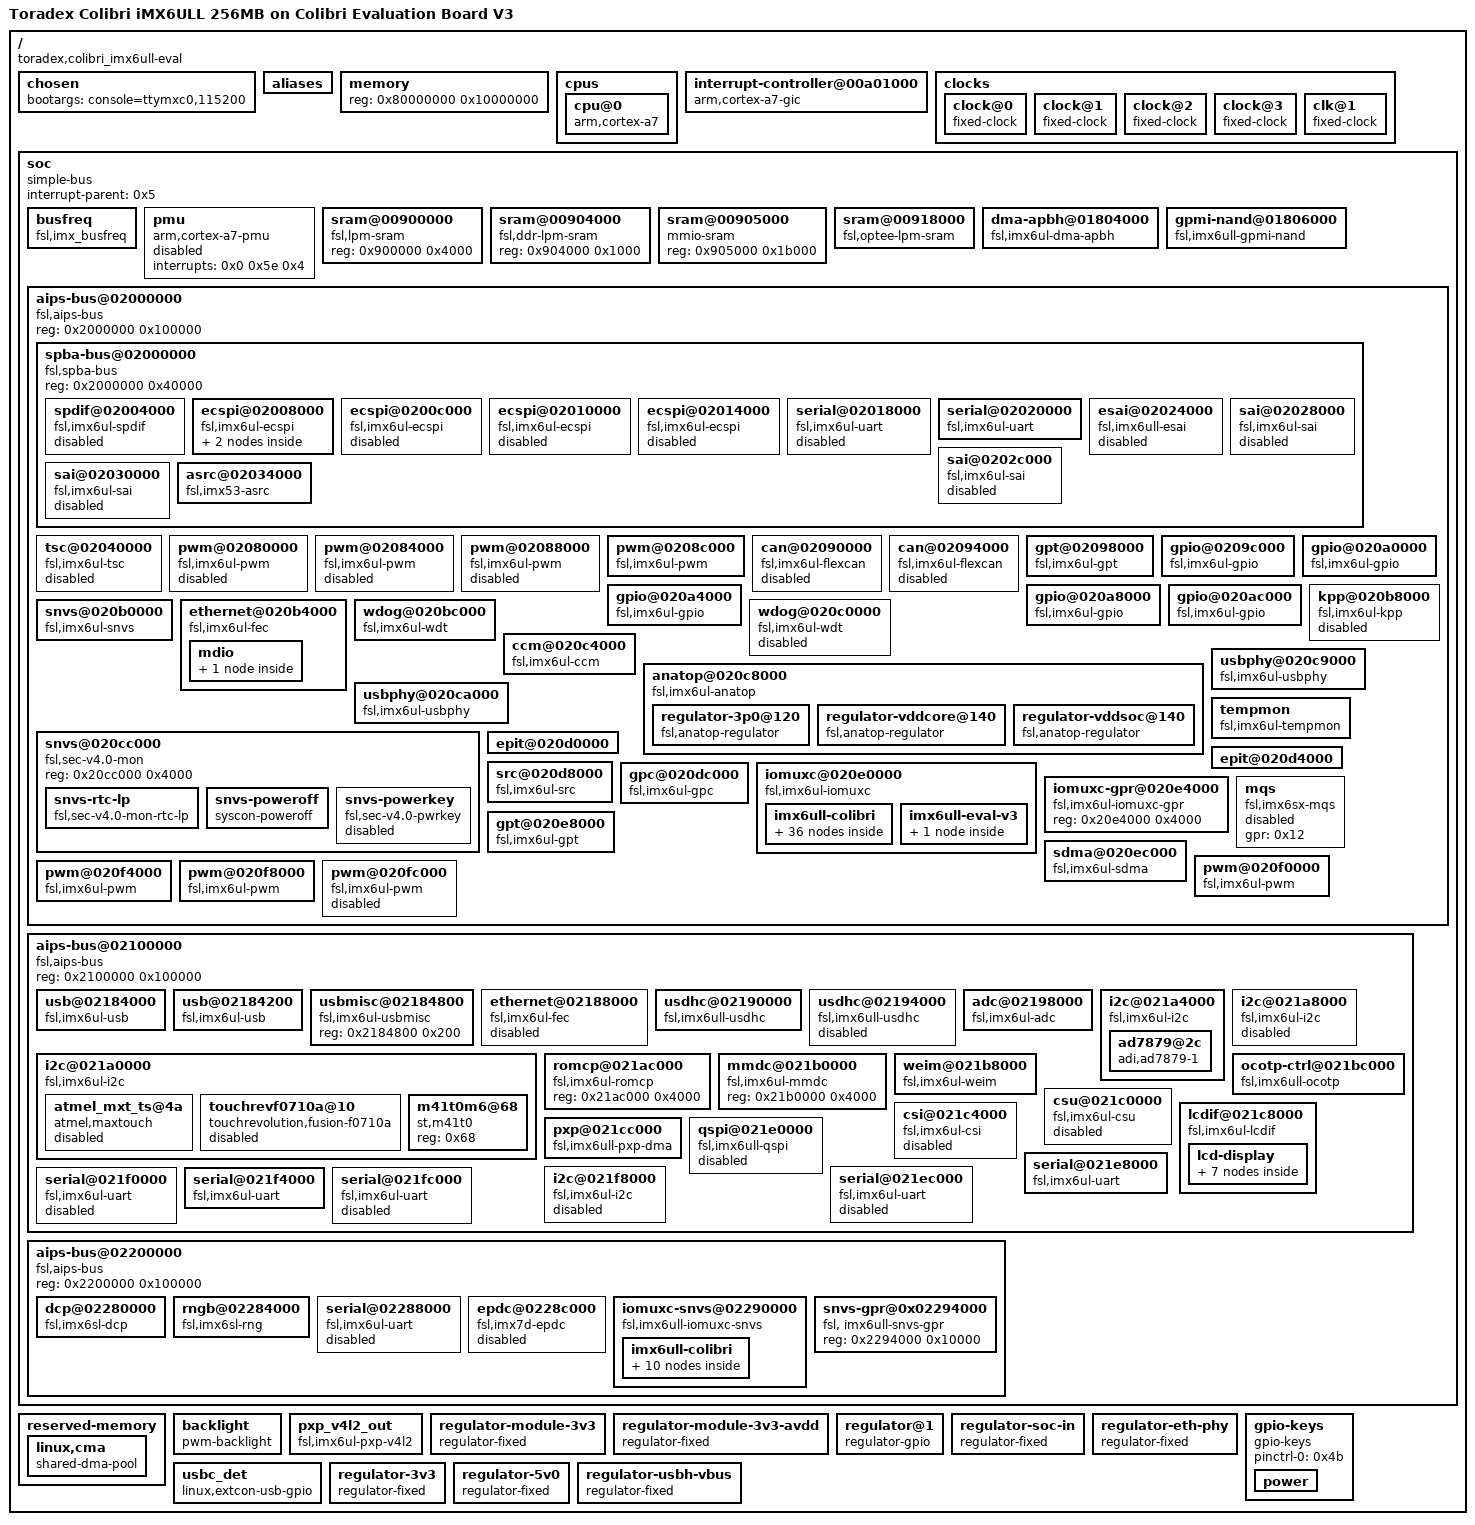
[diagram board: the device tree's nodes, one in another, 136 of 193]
/dts-v1/;

/ {
	#address-cells = <0x1>;
	#size-cells = <0x1>;
	model = "Toradex Colibri iMX6ULL 256MB on Colibri Evaluation Board V3";
	compatible = "toradex,colibri_imx6ull-eval", "fsl,imx6ull";

	chosen {
		bootargs = "console=ttymxc0,115200";
	};

	aliases {
		can0 = "/soc/aips-bus@02000000/can@02090000";
		can1 = "/soc/aips-bus@02000000/can@02094000";
		ethernet0 = "/soc/aips-bus@02000000/ethernet@020b4000";
		ethernet1 = "/soc/aips-bus@02100000/ethernet@02188000";
		gpio0 = "/soc/aips-bus@02000000/gpio@0209c000";
		gpio1 = "/soc/aips-bus@02000000/gpio@020a0000";
		gpio2 = "/soc/aips-bus@02000000/gpio@020a4000";
		gpio3 = "/soc/aips-bus@02000000/gpio@020a8000";
		gpio4 = "/soc/aips-bus@02000000/gpio@020ac000";
		i2c0 = "/soc/aips-bus@02100000/i2c@021a0000";
		i2c1 = "/soc/aips-bus@02100000/i2c@021a4000";
		i2c2 = "/soc/aips-bus@02100000/i2c@021a8000";
		i2c3 = "/soc/aips-bus@02100000/i2c@021f8000";
		mmc0 = "/soc/aips-bus@02100000/usdhc@02190000";
		mmc1 = "/soc/aips-bus@02100000/usdhc@02194000";
		serial0 = "/soc/aips-bus@02000000/spba-bus@02000000/serial@02020000";
		serial1 = "/soc/aips-bus@02100000/serial@021e8000";
		serial2 = "/soc/aips-bus@02100000/serial@021ec000";
		serial3 = "/soc/aips-bus@02100000/serial@021f0000";
		serial4 = "/soc/aips-bus@02100000/serial@021f4000";
		serial5 = "/soc/aips-bus@02100000/serial@021fc000";
		serial6 = "/soc/aips-bus@02000000/spba-bus@02000000/serial@02018000";
		serial7 = "/soc/aips-bus@02200000/serial@02288000";
		spi0 = "/soc/aips-bus@02000000/spba-bus@02000000/ecspi@02008000";
		spi1 = "/soc/aips-bus@02000000/spba-bus@02000000/ecspi@0200c000";
		spi2 = "/soc/aips-bus@02000000/spba-bus@02000000/ecspi@02010000";
		spi3 = "/soc/aips-bus@02000000/spba-bus@02000000/ecspi@02014000";
		usbphy0 = "/soc/aips-bus@02000000/usbphy@020c9000";
		usbphy1 = "/soc/aips-bus@02000000/usbphy@020ca000";
	};

	memory {
		device_type = "memory";
		reg = <0x80000000 0x10000000>;
	};

	cpus {
		#address-cells = <0x1>;
		#size-cells = <0x0>;

		cpu@0 {
			compatible = "arm,cortex-a7";
			device_type = "cpu";
			reg = <0x0>;
			clock-latency = <0xee6c>;
			operating-points = <0xdbba0 0x137478 0xc15c0 0x12b128 0x80e80 0x11edd8 0x60ae0 0xfa3e8 0x30570 0xe7ef0>;
			fsl,soc-operating-points = <0xdbba0 0x11edd8 0xc15c0 0x11edd8 0x80e80 0x11edd8 0x60ae0 0x11edd8 0x30570 0x11edd8>;
			fsl,low-power-run;
			clocks = <0x1 0x5d 0x1 0x1a 0x1 0x26 0x1 0xdb 0x1 0x38 0x1 0x39 0x1 0x19 0x1 0x12 0x1 0xb 0x1 0x4 0x1 0x3>;
			clock-names = "arm", "pll2_bus", "pll2_pfd2_396m", "secondary_sel", "step", "pll1_sw", "pll1_sys", "pll1_bypass", "pll1", "pll1_bypass_src", "osc";
			arm-supply = <0x2>;
			soc-supply = <0x3>;
			dc-supply = <0x4>;
		};
	};

	interrupt-controller@00a01000 {
		compatible = "arm,cortex-a7-gic";
		#interrupt-cells = <0x3>;
		interrupt-controller;
		reg = <0xa01000 0x1000 0xa02000 0x100>;
		linux,phandle = <0x21>;
		phandle = <0x21>;
	};

	clocks {
		#address-cells = <0x1>;
		#size-cells = <0x0>;

		clock@0 {
			compatible = "fixed-clock";
			reg = <0x0>;
			#clock-cells = <0x0>;
			clock-frequency = <0x8000>;
			clock-output-names = "ckil";
			linux,phandle = <0x19>;
			phandle = <0x19>;
		};

		clock@1 {
			compatible = "fixed-clock";
			reg = <0x1>;
			#clock-cells = <0x0>;
			clock-frequency = <0x16e3600>;
			clock-output-names = "osc";
			linux,phandle = <0x1a>;
			phandle = <0x1a>;
		};

		clock@2 {
			compatible = "fixed-clock";
			reg = <0x2>;
			#clock-cells = <0x0>;
			clock-frequency = <0x0>;
			clock-output-names = "ipp_di0";
			linux,phandle = <0x1b>;
			phandle = <0x1b>;
		};

		clock@3 {
			compatible = "fixed-clock";
			reg = <0x3>;
			#clock-cells = <0x0>;
			clock-frequency = <0x0>;
			clock-output-names = "ipp_di1";
			linux,phandle = <0x1c>;
			phandle = <0x1c>;
		};

		clk@1 {
			compatible = "fixed-clock";
			reg = <0x1>;
			#clock-cells = <0x0>;
			clock-frequency = <0xf42400>;
			clock-output-names = "clk16m";
			linux,phandle = <0xe>;
			phandle = <0xe>;
		};
	};

	soc {
		#address-cells = <0x1>;
		#size-cells = <0x1>;
		compatible = "simple-bus";
		interrupt-parent = <0x5>;
		ranges;

		busfreq {
			compatible = "fsl,imx_busfreq";
			clocks = <0x1 0x26 0x1 0x35 0x1 0x1a 0x1 0x5d 0x1 0x1b 0x1 0x55 0x1 0x3c 0x1 0x5e 0x1 0x3e 0x1 0x3 0x1 0x60 0x1 0xd4 0x1 0x56 0x1 0x3d 0x1 0x5f 0x1 0x3f 0x1 0x38 0x1 0xa3 0x1 0x4 0x1 0x12 0x1 0x19 0x1 0x39 0x1 0xb>;
			clock-names = "pll2_pfd2_396m", "pll2_198m", "pll2_bus", "arm", "pll3_usb_otg", "periph", "periph_pre", "periph_clk2", "periph_clk2_sel", "osc", "ahb", "ocram", "periph2", "periph2_pre", "periph2_clk2", "periph2_clk2_sel", "step", "mmdc", "pll1_bypass_src", "pll1_bypass", "pll1_sys", "pll1_sw", "pll1";
			fsl,max_ddr_freq = <0x17d78400>;
		};

		pmu {
			compatible = "arm,cortex-a7-pmu";
			interrupts = <0x0 0x5e 0x4>;
			status = "disabled";
		};

		sram@00900000 {
			compatible = "fsl,lpm-sram";
			reg = <0x900000 0x4000>;
		};

		sram@00904000 {
			compatible = "fsl,ddr-lpm-sram";
			reg = <0x904000 0x1000>;
		};

		sram@00905000 {
			compatible = "mmio-sram";
			reg = <0x905000 0x1b000>;
			linux,phandle = <0x6>;
			phandle = <0x6>;
		};

		sram@00918000 {
			compatible = "fsl,optee-lpm-sram";
			reg = <0x918000 0x8000>;
			overw_reg = <0x6 0x905000 0x13000>;
		};

		dma-apbh@01804000 {
			compatible = "fsl,imx6ul-dma-apbh", "fsl,imx28-dma-apbh";
			reg = <0x1804000 0x2000>;
			interrupts = <0x0 0xd 0x4 0x0 0xd 0x4 0x0 0xd 0x4 0x0 0xd 0x4>;
			interrupt-names = "gpmi0", "gpmi1", "gpmi2", "gpmi3";
			#dma-cells = <0x1>;
			dma-channels = <0x4>;
			clocks = <0x1 0x80>;
			linux,phandle = <0x7>;
			phandle = <0x7>;
		};

		gpmi-nand@01806000 {
			compatible = "fsl,imx6ull-gpmi-nand", "fsl, imx6ul-gpmi-nand";
			#address-cells = <0x1>;
			#size-cells = <0x1>;
			reg = <0x1806000 0x2000 0x1808000 0x4000>;
			reg-names = "gpmi-nand", "bch";
			interrupts = <0x0 0xf 0x4>;
			interrupt-names = "bch";
			clocks = <0x1 0x85 0x1 0x86 0x1 0x84 0x1 0x83 0x1 0xdc>;
			clock-names = "gpmi_io", "gpmi_apb", "gpmi_bch", "gpmi_bch_apb", "per1_bch";
			dmas = <0x7 0x0>;
			dma-names = "rx-tx";
			status = "okay";
			pinctrl-names = "default";
			pinctrl-0 = <0x8>;
			nand-on-flash-bbt;
			nand-ecc-mode = "hw";
		};

		aips-bus@02000000 {
			compatible = "fsl,aips-bus", "simple-bus";
			#address-cells = <0x1>;
			#size-cells = <0x1>;
			reg = <0x2000000 0x100000>;
			ranges;

			spba-bus@02000000 {
				compatible = "fsl,spba-bus", "simple-bus";
				#address-cells = <0x1>;
				#size-cells = <0x1>;
				reg = <0x2000000 0x40000>;
				ranges;

				spdif@02004000 {
					compatible = "fsl,imx6ul-spdif", "fsl,imx35-spdif";
					reg = <0x2004000 0x4000>;
					interrupts = <0x0 0x34 0x4>;
					dmas = <0x9 0x29 0x12 0x0 0x9 0x2a 0x12 0x0>;
					dma-names = "rx", "tx";
					clocks = <0x1 0xd5 0x1 0x3 0x1 0xbc 0x1 0x0 0x1 0x0 0x1 0x0 0x1 0x64 0x1 0x0 0x1 0x0 0x1 0xbb>;
					clock-names = "core", "rxtx0", "rxtx1", "rxtx2", "rxtx3", "rxtx4", "rxtx5", "rxtx6", "rxtx7", "spba";
					status = "disabled";
				};

				ecspi@02008000 {
					#address-cells = <0x1>;
					#size-cells = <0x0>;
					compatible = "fsl,imx6ul-ecspi", "fsl,imx51-ecspi";
					reg = <0x2008000 0x4000>;
					interrupts = <0x0 0x1f 0x4>;
					clocks = <0x1 0x8b 0x1 0x8b>;
					clock-names = "ipg", "per";
					dmas = <0x9 0x3 0x7 0x1 0x9 0x4 0x7 0x2>;
					dma-names = "rx", "tx";
					status = "okay";
					fsl,spi-num-chipselects = <0x1>;
					cs-gpios = <0xa 0x1a 0x0>;
					pinctrl-names = "default";
					pinctrl-0 = <0xb 0xc>;

					mcp251x@0 {
						compatible = "microchip,mcp2515";
						pinctrl-names = "default";
						pinctrl-0 = <0xd>;
						reg = <0x0>;
						clocks = <0xe>;
						interrupt-parent = <0xf>;
						interrupts = <0x4 0x2>;
						spi-max-frequency = <0x989680>;
						status = "okay";
					};

					spidev@0 {
						compatible = "toradex,evalspi";
						reg = <0x0>;
						spi-max-frequency = <0x15ef3c0>;
						status = "disabled";
					};
				};

				ecspi@0200c000 {
					#address-cells = <0x1>;
					#size-cells = <0x0>;
					compatible = "fsl,imx6ul-ecspi", "fsl,imx51-ecspi";
					reg = <0x200c000 0x4000>;
					interrupts = <0x0 0x20 0x4>;
					clocks = <0x1 0x8c 0x1 0x8c>;
					clock-names = "ipg", "per";
					dmas = <0x9 0x5 0x7 0x1 0x9 0x6 0x7 0x2>;
					dma-names = "rx", "tx";
					status = "disabled";
				};

				ecspi@02010000 {
					#address-cells = <0x1>;
					#size-cells = <0x0>;
					compatible = "fsl,imx6ul-ecspi", "fsl,imx51-ecspi";
					reg = <0x2010000 0x4000>;
					interrupts = <0x0 0x21 0x4>;
					clocks = <0x1 0x8d 0x1 0x8d>;
					clock-names = "ipg", "per";
					dmas = <0x9 0x7 0x7 0x1 0x9 0x8 0x7 0x2>;
					dma-names = "rx", "tx";
					status = "disabled";
				};

				ecspi@02014000 {
					#address-cells = <0x1>;
					#size-cells = <0x0>;
					compatible = "fsl,imx6ul-ecspi", "fsl,imx51-ecspi";
					reg = <0x2014000 0x4000>;
					interrupts = <0x0 0x22 0x4>;
					clocks = <0x1 0x8e 0x1 0x8e>;
					clock-names = "ipg", "per";
					dmas = <0x9 0x9 0x7 0x1 0x9 0xa 0x7 0x2>;
					dma-names = "rx", "tx";
					status = "disabled";
				};

				serial@02018000 {
					compatible = "fsl,imx6ul-uart", "fsl,imx6q-uart", "fsl,imx21-uart";
					reg = <0x2018000 0x4000>;
					interrupts = <0x0 0x27 0x4>;
					clocks = <0x1 0xc9 0x1 0xca>;
					clock-names = "ipg", "per";
					dmas = <0x9 0x2b 0x4 0x0 0x9 0x2c 0x4 0x0>;
					dma-names = "rx", "tx";
					status = "disabled";
				};

				serial@02020000 {
					compatible = "fsl,imx6ul-uart", "fsl,imx6q-uart", "fsl,imx21-uart";
					reg = <0x2020000 0x4000>;
					interrupts = <0x0 0x1a 0x4>;
					clocks = <0x1 0xbd 0x1 0xbe>;
					clock-names = "ipg", "per";
					status = "okay";
					pinctrl-names = "default";
					pinctrl-0 = <0x10 0x11>;
					fsl,uart-has-rtscts;
					fsl,dte-mode;
				};

				esai@02024000 {
					compatible = "fsl,imx6ull-esai";
					reg = <0x2024000 0x4000>;
					interrupts = <0x0 0x33 0x4>;
					clocks = <0x1 0xe6 0x1 0xe5 0x1 0xe4 0x1 0xe6 0x1 0xbb>;
					clock-names = "core", "mem", "extal", "fsys", "spba";
					dmas = <0x9 0x0 0x15 0x0 0x9 0x2f 0x15 0x0>;
					dma-names = "rx", "tx";
					dma-source = <0x12 0x0 0xe 0x0 0xf>;
					status = "disabled";
				};

				sai@02028000 {
					compatible = "fsl,imx6ul-sai", "fsl,imx6sx-sai";
					reg = <0x2028000 0x4000>;
					interrupts = <0x0 0x61 0x4>;
					clocks = <0x1 0xb3 0x1 0x0 0x1 0xb2 0x1 0x0 0x1 0x0>;
					clock-names = "bus", "mclk0", "mclk1", "mclk2", "mclk3";
					dma-names = "rx", "tx";
					dmas = <0x9 0x23 0x18 0x0 0x9 0x24 0x18 0x0>;
					status = "disabled";
				};

				sai@0202c000 {
					compatible = "fsl,imx6ul-sai", "fsl,imx6sx-sai";
					reg = <0x202c000 0x4000>;
					interrupts = <0x0 0x62 0x4>;
					clocks = <0x1 0xb5 0x1 0x0 0x1 0xb4 0x1 0x0 0x1 0x0>;
					clock-names = "bus", "mclk0", "mclk1", "mclk2", "mclk3";
					dma-names = "rx", "tx";
					dmas = <0x9 0x25 0x18 0x0 0x9 0x26 0x18 0x0>;
					status = "disabled";
				};

				sai@02030000 {
					compatible = "fsl,imx6ul-sai", "fsl,imx6sx-sai";
					reg = <0x2030000 0x4000>;
					interrupts = <0x0 0x18 0x4>;
					clocks = <0x1 0xb7 0x1 0x0 0x1 0xb6 0x1 0x0 0x1 0x0>;
					clock-names = "bus", "mclk0", "mclk1", "mclk2", "mclk3";
					dma-names = "rx", "tx";
					dmas = <0x9 0x27 0x18 0x0 0x9 0x28 0x18 0x0>;
					status = "disabled";
				};

				asrc@02034000 {
					compatible = "fsl,imx53-asrc";
					reg = <0x2034000 0x4000>;
					interrupts = <0x0 0x32 0x4>;
					clocks = <0x1 0x81 0x1 0x82 0x1 0x0 0x1 0x0 0x1 0x0 0x1 0x0 0x1 0x0 0x1 0x0 0x1 0x0 0x1 0x0 0x1 0x0 0x1 0x0 0x1 0x0 0x1 0x0 0x1 0x0 0x1 0xbc 0x1 0x0 0x1 0x0 0x1 0xbb>;
					clock-names = "mem", "ipg", "asrck_0", "asrck_1", "asrck_2", "asrck_3", "asrck_4", "asrck_5", "asrck_6", "asrck_7", "asrck_8", "asrck_9", "asrck_a", "asrck_b", "asrck_c", "asrck_d", "asrck_e", "asrck_f", "spba";
					dmas = <0x9 0x11 0x17 0x1 0x9 0x12 0x17 0x1 0x9 0x13 0x17 0x1 0x9 0x14 0x17 0x1 0x9 0x15 0x17 0x1 0x9 0x16 0x17 0x1>;
					dma-names = "rxa", "rxb", "rxc", "txa", "txb", "txc";
					fsl,asrc-rate = <0xbb80>;
					fsl,asrc-width = <0x10>;
					status = "okay";
				};
			};

			tsc@02040000 {
				compatible = "fsl,imx6ul-tsc";
				reg = <0x2040000 0x4000 0x219c000 0x4000>;
				interrupts = <0x0 0x3 0x4 0x0 0x65 0x4>;
				clocks = <0x1 0x64 0x1 0x7c>;
				clock-names = "tsc", "adc";
				status = "disabled";
			};

			pwm@02080000 {
				compatible = "fsl,imx6ul-pwm", "fsl,imx27-pwm";
				reg = <0x2080000 0x4000>;
				interrupts = <0x0 0x53 0x4>;
				clocks = <0x1 0xa7 0x1 0xa7>;
				clock-names = "ipg", "per";
				#pwm-cells = <0x3>;
				status = "disabled";
			};

			pwm@02084000 {
				compatible = "fsl,imx6ul-pwm", "fsl,imx27-pwm";
				reg = <0x2084000 0x4000>;
				interrupts = <0x0 0x54 0x4>;
				clocks = <0x1 0xa8 0x1 0xa8>;
				clock-names = "ipg", "per";
				#pwm-cells = <0x3>;
				status = "disabled";
			};

			pwm@02088000 {
				compatible = "fsl,imx6ul-pwm", "fsl,imx27-pwm";
				reg = <0x2088000 0x4000>;
				interrupts = <0x0 0x55 0x4>;
				clocks = <0x1 0xa9 0x1 0xa9>;
				clock-names = "ipg", "per";
				#pwm-cells = <0x3>;
				status = "disabled";
			};

			pwm@0208c000 {
				compatible = "fsl,imx6ul-pwm", "fsl,imx27-pwm";
				reg = <0x208c000 0x4000>;
				interrupts = <0x0 0x56 0x4>;
				clocks = <0x1 0xaa 0x1 0xaa>;
				clock-names = "ipg", "per";
				#pwm-cells = <0x3>;
				pinctrl-names = "default";
				pinctrl-0 = <0x13>;
				status = "okay";
				linux,phandle = <0x48>;
				phandle = <0x48>;
			};

			can@02090000 {
				compatible = "fsl,imx6ul-flexcan", "fsl,imx6q-flexcan";
				reg = <0x2090000 0x4000>;
				interrupts = <0x0 0x6e 0x4>;
				clocks = <0x1 0x94 0x1 0x95>;
				clock-names = "ipg", "per";
				stop-mode = <0x12 0x10 0x1 0x10 0x11>;
				status = "disabled";
			};

			can@02094000 {
				compatible = "fsl,imx6ul-flexcan", "fsl,imx6q-flexcan";
				reg = <0x2094000 0x4000>;
				interrupts = <0x0 0x6f 0x4>;
				clocks = <0x1 0x96 0x1 0x97>;
				clock-names = "ipg", "per";
				stop-mode = <0x12 0x10 0x2 0x10 0x12>;
				status = "disabled";
			};

			gpt@02098000 {
				compatible = "fsl,imx6ul-gpt", "fsl,imx31-gpt";
				reg = <0x2098000 0x4000>;
				interrupts = <0x0 0x37 0x4>;
				clocks = <0x1 0x98 0x1 0xd6>;
				clock-names = "ipg", "osc_per";
			};

			gpio@0209c000 {
				compatible = "fsl,imx6ul-gpio", "fsl,imx35-gpio";
				reg = <0x209c000 0x4000>;
				interrupts = <0x0 0x42 0x4 0x0 0x43 0x4>;
				gpio-controller;
				#gpio-cells = <0x2>;
				interrupt-controller;
				#interrupt-cells = <0x2>;
				linux,phandle = <0x38>;
				phandle = <0x38>;
			};

			gpio@020a0000 {
				compatible = "fsl,imx6ul-gpio", "fsl,imx35-gpio";
				reg = <0x20a0000 0x4000>;
				interrupts = <0x0 0x44 0x4 0x0 0x45 0x4>;
				gpio-controller;
				#gpio-cells = <0x2>;
				interrupt-controller;
				#interrupt-cells = <0x2>;
				linux,phandle = <0xf>;
				phandle = <0xf>;
			};

			gpio@020a4000 {
				compatible = "fsl,imx6ul-gpio", "fsl,imx35-gpio";
				reg = <0x20a4000 0x4000>;
				interrupts = <0x0 0x46 0x4 0x0 0x47 0x4>;
				gpio-controller;
				#gpio-cells = <0x2>;
				interrupt-controller;
				#interrupt-cells = <0x2>;
				linux,phandle = <0xa>;
				phandle = <0xa>;
			};

			gpio@020a8000 {
				compatible = "fsl,imx6ul-gpio", "fsl,imx35-gpio";
				reg = <0x20a8000 0x4000>;
				interrupts = <0x0 0x48 0x4 0x0 0x49 0x4>;
				gpio-controller;
				#gpio-cells = <0x2>;
				interrupt-controller;
				#interrupt-cells = <0x2>;
				linux,phandle = <0x3a>;
				phandle = <0x3a>;
			};

			gpio@020ac000 {
				compatible = "fsl,imx6ul-gpio", "fsl,imx35-gpio";
				reg = <0x20ac000 0x4000>;
				interrupts = <0x0 0x4a 0x4 0x0 0x4b 0x4>;
				gpio-controller;
				#gpio-cells = <0x2>;
				interrupt-controller;
				#interrupt-cells = <0x2>;
				linux,phandle = <0x33>;
				phandle = <0x33>;
			};

			snvs@020b0000 {
				compatible = "fsl,imx6ul-snvs";
				reg = <0x20b0000 0x4000>;
				interrupts = <0x0 0x4 0x4>;
			};

			ethernet@020b4000 {
				compatible = "fsl,imx6ul-fec", "fsl,imx6q-fec";
				reg = <0x20b4000 0x4000>;
				interrupts = <0x0 0x78 0x4 0x0 0x79 0x4>;
				clocks = <0x1 0x90 0x1 0x91 0x1 0x30 0x1 0x2e 0x1 0x2e>;
				clock-names = "ipg", "ahb", "ptp", "enet_clk_ref", "enet_out";
				stop-mode = <0x12 0x10 0x4>;
				fsl,num-tx-queues = <0x1>;
				fsl,num-rx-queues = <0x1>;
				fsl,magic-packet;
				fsl,wakeup_irq = <0x0>;
				status = "okay";
				pinctrl-names = "default", "sleep";
				pinctrl-0 = <0x14>;
				pinctrl-1 = <0x15>;
				phy-mode = "rmii";
				phy-handle = <0x16>;
				phy-supply = <0x17>;

				mdio {
					#address-cells = <0x1>;
					#size-cells = <0x0>;

					ethernet-phy@2 {
						compatible = "ethernet-phy-ieee802.3-c22";
						max-speed = <0x64>;
						reg = <0x2>;
						linux,phandle = <0x16>;
						phandle = <0x16>;
					};
				};
			};

			kpp@020b8000 {
				compatible = "fsl,imx6ul-kpp", "fsl,imx21-kpp";
				reg = <0x20b8000 0x4000>;
				interrupts = <0x0 0x52 0x4>;
				clocks = <0x1 0x0>;
				status = "disabled";
			};

			wdog@020bc000 {
				compatible = "fsl,imx6ul-wdt", "fsl,imx21-wdt";
				reg = <0x20bc000 0x4000>;
				interrupts = <0x0 0x50 0x4>;
				clocks = <0x1 0xd0>;
				pinctrl-names = "default";
				pinctrl-0 = <0x18>;
				fsl,ext-reset-output;
			};

			wdog@020c0000 {
				compatible = "fsl,imx6ul-wdt", "fsl,imx21-wdt";
				reg = <0x20c0000 0x4000>;
				interrupts = <0x0 0x51 0x4>;
				clocks = <0x1 0xd1>;
				status = "disabled";
			};

			ccm@020c4000 {
				compatible = "fsl,imx6ul-ccm";
				reg = <0x20c4000 0x4000>;
				interrupts = <0x0 0x57 0x4 0x0 0x58 0x4>;
				#clock-cells = <0x1>;
				clocks = <0x19 0x1a 0x1b 0x1c>;
				clock-names = "ckil", "osc", "ipp_di0", "ipp_di1";
				linux,phandle = <0x1>;
				phandle = <0x1>;
			};

			anatop@020c8000 {
				compatible = "fsl,imx6ul-anatop", "fsl,imx6q-anatop", "syscon", "simple-bus";
				reg = <0x20c8000 0x1000>;
				interrupts = <0x0 0x31 0x4 0x0 0x36 0x4 0x0 0x7f 0x4>;
				linux,phandle = <0x1e>;
				phandle = <0x1e>;

				regulator-3p0@120 {
					compatible = "fsl,anatop-regulator";
					regulator-name = "vdd3p0";
					regulator-min-microvolt = <0x280de8>;
					regulator-max-microvolt = <0x33e140>;
					anatop-reg-offset = <0x120>;
					anatop-vol-bit-shift = <0x8>;
					anatop-vol-bit-width = <0x5>;
					anatop-min-bit-val = <0x0>;
					anatop-min-voltage = <0x280de8>;
					anatop-max-voltage = <0x33e140>;
					anatop-enable-bit = <0x0>;
					linux,phandle = <0x1d>;
					phandle = <0x1d>;
				};

				regulator-vddcore@140 {
					compatible = "fsl,anatop-regulator";
					regulator-name = "cpu";
					regulator-min-microvolt = <0xb1008>;
					regulator-max-microvolt = <0x162010>;
					regulator-always-on;
					anatop-reg-offset = <0x140>;
					anatop-vol-bit-shift = <0x0>;
					anatop-vol-bit-width = <0x5>;
					anatop-delay-reg-offset = <0x170>;
					anatop-delay-bit-shift = <0x18>;
					anatop-delay-bit-width = <0x2>;
					anatop-min-bit-val = <0x1>;
					anatop-min-voltage = <0xb1008>;
					anatop-max-voltage = <0x162010>;
					linux,phandle = <0x2>;
					phandle = <0x2>;
				};

				regulator-vddsoc@140 {
					compatible = "fsl,anatop-regulator";
					regulator-name = "vddsoc";
					regulator-min-microvolt = <0xb1008>;
					regulator-max-microvolt = <0x162010>;
					regulator-always-on;
					anatop-reg-offset = <0x140>;
					anatop-vol-bit-shift = <0x12>;
					anatop-vol-bit-width = <0x5>;
					anatop-delay-reg-offset = <0x170>;
					anatop-delay-bit-shift = <0x1c>;
					anatop-delay-bit-width = <0x2>;
					anatop-min-bit-val = <0x1>;
					anatop-min-voltage = <0xb1008>;
					anatop-max-voltage = <0x162010>;
					linux,phandle = <0x3>;
					phandle = <0x3>;
				};
			};

			usbphy@020c9000 {
				compatible = "fsl,imx6ul-usbphy", "fsl,imx23-usbphy";
				reg = <0x20c9000 0x1000>;
				interrupts = <0x0 0x2c 0x4>;
				clocks = <0x1 0x20>;
				phy-3p0-supply = <0x1d>;
				fsl,anatop = <0x1e>;
				linux,phandle = <0x2c>;
				phandle = <0x2c>;
			};

			usbphy@020ca000 {
				compatible = "fsl,imx6ul-usbphy", "fsl,imx23-usbphy";
				reg = <0x20ca000 0x1000>;
				interrupts = <0x0 0x2d 0x4>;
				clocks = <0x1 0x21>;
				phy-3p0-supply = <0x1d>;
				fsl,anatop = <0x1e>;
				linux,phandle = <0x30>;
				phandle = <0x30>;
			};

			tempmon {
				compatible = "fsl,imx6ul-tempmon", "fsl,imx6sx-tempmon";
				interrupts = <0x0 0x31 0x4>;
				fsl,tempmon = <0x1e>;
				fsl,tempmon-data = <0x1f>;
				clocks = <0x1 0x1b>;
			};

			snvs@020cc000 {
				compatible = "fsl,sec-v4.0-mon", "syscon", "simple-mfd";
				reg = <0x20cc000 0x4000>;
				linux,phandle = <0x20>;
				phandle = <0x20>;

				snvs-rtc-lp {
					compatible = "fsl,sec-v4.0-mon-rtc-lp";
					regmap = <0x20>;
					offset = <0x34>;
					interrupts = <0x0 0x13 0x4 0x0 0x14 0x4>;
				};

				snvs-poweroff {
					compatible = "syscon-poweroff";
					regmap = <0x20>;
					offset = <0x38>;
					mask = <0x61>;
				};

				snvs-powerkey {
					compatible = "fsl,sec-v4.0-pwrkey";
					regmap = <0x20>;
					interrupts = <0x0 0x4 0x4>;
					linux,keycode = <0x74>;
					wakeup-source;
					status = "disabled";
				};
			};

			epit@020d0000 {
				reg = <0x20d0000 0x4000>;
				interrupts = <0x0 0x38 0x4>;
			};

			epit@020d4000 {
				reg = <0x20d4000 0x4000>;
				interrupts = <0x0 0x39 0x4>;
			};

			src@020d8000 {
				compatible = "fsl,imx6ul-src", "fsl,imx51-src";
				reg = <0x20d8000 0x4000>;
				interrupts = <0x0 0x5b 0x4 0x0 0x60 0x4>;
				#reset-cells = <0x1>;
			};

			gpc@020dc000 {
				compatible = "fsl,imx6ul-gpc", "fsl,imx6q-gpc";
				reg = <0x20dc000 0x4000>;
				interrupt-controller;
				#interrupt-cells = <0x3>;
				interrupts = <0x0 0x59 0x4>;
				interrupt-parent = <0x21>;
				fsl,mf-mix-wakeup-irq = <0xfc00000 0x7d00 0x0 0x1400640>;
				fsl,cpu_pupscr_sw2iso = <0x1>;
				fsl,cpu_pupscr_sw = <0x0>;
				fsl,cpu_pdnscr_iso2sw = <0x1>;
				fsl,cpu_pdnscr_iso = <0x1>;
				fsl,ldo-bypass = <0x0>;
				linux,phandle = <0x5>;
				phandle = <0x5>;
			};

			iomuxc@020e0000 {
				compatible = "fsl,imx6ul-iomuxc";
				reg = <0x20e0000 0x4000>;
				pinctrl-names = "default";
				pinctrl-0 = <0x22 0x23 0x24 0x25 0x26 0x27 0x28>;

				imx6ull-colibri {

					hoggrp-1 {
						fsl,pins = <0xa8 0x334 0x0 0x5 0x0 0x14 0x54 0x2e0 0x0 0x5 0x0 0x14 0x1b0 0x43c 0x0 0x5 0x0 0x14 0xa4 0x330 0x0 0x5 0x0 0x14 0xac 0x338 0x0 0x5 0x0 0x14 0x58 0x2e4 0x0 0x5 0x0 0x14 0xe0 0x36c 0x0 0x5 0x0 0x14 0xb0 0x33c 0x0 0x5 0x0 0x14>;
						linux,phandle = <0x22>;
						phandle = <0x22>;
					};

					hoggrp-2 {
						fsl,pins = <0x1f4 0x480 0x0 0x5 0x0 0x74 0x1d4 0x460 0x0 0x5 0x0 0x14 0x1fc 0x488 0x0 0x5 0x0 0x14 0x1d8 0x464 0x0 0x5 0x0 0x14 0x1f8 0x484 0x0 0x5 0x0 0x14>;
						linux,phandle = <0x23>;
						phandle = <0x23>;
					};

					hoggrp-3 {
						fsl,pins = <0xcc 0x358 0x0 0x5 0x0 0x14 0xd0 0x35c 0x0 0x5 0x0 0x14>;
						linux,phandle = <0x24>;
						phandle = <0x24>;
					};

					hoggrp-4 {
						fsl,pins = <0x200 0x48c 0x0 0x5 0x0 0x74>;
						linux,phandle = <0x25>;
						phandle = <0x25>;
					};

					hoggrp-5 {
						fsl,pins = <0x44 0x2d0 0x0 0x5 0x0 0x74>;
						linux,phandle = <0x26>;
						phandle = <0x26>;
					};

					hoggrp-6 {
						fsl,pins = <0x68 0x2f4 0x0 0x5 0x0 0x14 0x1ec 0x478 0x0 0x5 0x0 0x14 0x1dc 0x468 0x0 0x5 0x0 0x14 0x1f0 0x47c 0x0 0x5 0x0 0x14 0x1e4 0x470 0x0 0x5 0x0 0x14 0x1e8 0x474 0x0 0x5 0x0 0x14 0x1e0 0x46c 0x0 0x5 0x0 0x14>;
						linux,phandle = <0x27>;
						phandle = <0x27>;
					};

					hoggrp-7 {
						fsl,pins = <0xc4 0x350 0x0 0x5 0x0 0x74 0xc8 0x354 0x0 0x5 0x0 0x74>;
						linux,phandle = <0x28>;
						phandle = <0x28>;
					};

					canintgrp {
						fsl,pins = <0xd4 0x360 0x0 0x5 0x0 0x14>;
						linux,phandle = <0xd>;
						phandle = <0xd>;
					};

					enet2grp {
						fsl,pins = <0x74 0x300 0x580 0x1 0x0 0x1b0b0 0x78 0x304 0x0 0x1 0x0 0x1b0b0 0xe4 0x370 0x0 0x0 0x0 0x1b0b0 0xe8 0x374 0x0 0x0 0x0 0x1b0b0 0xec 0x378 0x0 0x0 0x0 0x1b0b0 0x100 0x38c 0x0 0x0 0x0 0x1b0b0 0xfc 0x388 0x57c 0x4 0x2 0x4001b031 0xf0 0x37c 0x0 0x0 0x0 0x1b0b0 0xf4 0x380 0x0 0x0 0x0 0x1b0b0 0xf8 0x384 0x0 0x0 0x0 0x1b0b0>;
						linux,phandle = <0x14>;
						phandle = <0x14>;
					};

					enet2sleepgrp {
						fsl,pins = <0x74 0x300 0x0 0x5 0x0 0x0 0x78 0x304 0x0 0x5 0x0 0x0 0xe4 0x370 0x0 0x5 0x0 0x0 0xe8 0x374 0x0 0x5 0x0 0x0 0xec 0x378 0x0 0x5 0x0 0x0 0x100 0x38c 0x0 0x5 0x0 0x0 0xfc 0x388 0x57c 0x4 0x2 0x4001b031 0xf0 0x37c 0x0 0x5 0x0 0x0 0xf4 0x380 0x0 0x5 0x0 0x0 0xf8 0x384 0x0 0x5 0x0 0x0>;
						linux,phandle = <0x15>;
						phandle = <0x15>;
					};

					ecspi1_cs_grp {
						fsl,pins = <0x16c 0x3f8 0x0 0x5 0x0 0xa0>;
						linux,phandle = <0xc>;
						phandle = <0xc>;
					};

					ecspi1grp {
						fsl,pins = <0x168 0x3f4 0x534 0x2 0x0 0xa0 0x170 0x3fc 0x53c 0x2 0x0 0xa0 0x174 0x400 0x538 0x2 0x0 0x100a0>;
						linux,phandle = <0xb>;
						phandle = <0xb>;
					};

					flexcan1grp {
						fsl,pins = <0xc4 0x350 0x0 0x4 0x0 0x1b020 0xc8 0x354 0x584 0x4 0x1 0x1b020>;
					};

					flexcan2grp {
						fsl,pins = <0xd0 0x35c 0x588 0x4 0x1 0x1b020 0xcc 0x358 0x0 0x4 0x0 0x1b020>;
					};

					gpio-bl-on {
						fsl,pins = <0x48 0x2d4 0x0 0x5 0x0 0xa0>;
						linux,phandle = <0x47>;
						phandle = <0x47>;
					};

					gpmi-nand-1 {
						fsl,pins = <0x180 0x40c 0x0 0x0 0x0 0x100a9 0x184 0x410 0x0 0x0 0x0 0x100a9 0x188 0x414 0x0 0x0 0x0 0x100a9 0x18c 0x418 0x0 0x0 0x0 0x100a9 0x190 0x41c 0x0 0x0 0x0 0x100a9 0x194 0x420 0x0 0x0 0x0 0x100a9 0x198 0x424 0x0 0x0 0x0 0x100a9 0x19c 0x428 0x0 0x0 0x0 0x100a9 0x1b4 0x440 0x0 0x0 0x0 0x100a9 0x1a0 0x42c 0x0 0x0 0x0 0x100a9 0x178 0x404 0x0 0x0 0x0 0x100a9 0x17c 0x408 0x0 0x0 0x0 0x100a9 0x1ac 0x438 0x0 0x0 0x0 0x100a9 0x1a8 0x434 0x0 0x0 0x0 0x100a9>;
						linux,phandle = <0x8>;
						phandle = <0x8>;
					};

					i2c1grp {
						fsl,pins = <0xb4 0x340 0x5a4 0x2 0x1 0x4001b8b0 0xb8 0x344 0x5a8 0x2 0x2 0x4001b8b0>;
						linux,phandle = <0x36>;
						phandle = <0x36>;
					};

					i2c1-gpio-grp {
						fsl,pins = <0xb4 0x340 0x0 0x5 0x0 0x4001b8b0 0xb8 0x344 0x0 0x5 0x0 0x4001b8b0>;
						linux,phandle = <0x37>;
						phandle = <0x37>;
					};

					i2c2grp {
						fsl,pins = <0xbc 0x348 0x5ac 0x2 0x2 0x4001f8b0 0xc0 0x34c 0x5b0 0x2 0x2 0x4001f8b0>;
						linux,phandle = <0x3b>;
						phandle = <0x3b>;
					};

					i2c2-gpio-grp {
						fsl,pins = <0xbc 0x348 0x0 0x5 0x0 0x4001f8b0 0xc0 0x34c 0x0 0x5 0x0 0x4001f8b0>;
						linux,phandle = <0x3c>;
						phandle = <0x3c>;
					};

					lcdifdatgrp {
						fsl,pins = <0x118 0x3a4 0x0 0x0 0x0 0x79 0x11c 0x3a8 0x0 0x0 0x0 0x79 0x120 0x3ac 0x0 0x0 0x0 0x79 0x124 0x3b0 0x0 0x0 0x0 0x79 0x128 0x3b4 0x0 0x0 0x0 0x79 0x12c 0x3b8 0x0 0x0 0x0 0x79 0x130 0x3bc 0x0 0x0 0x0 0x79 0x134 0x3c0 0x0 0x0 0x0 0x79 0x138 0x3c4 0x0 0x0 0x0 0x79 0x13c 0x3c8 0x0 0x0 0x0 0x79 0x140 0x3cc 0x0 0x0 0x0 0x79 0x144 0x3d0 0x0 0x0 0x0 0x79 0x148 0x3d4 0x0 0x0 0x0 0x79 0x14c 0x3d8 0x0 0x0 0x0 0x79 0x150 0x3dc 0x0 0x0 0x0 0x79 0x154 0x3e0 0x0 0x0 0x0 0x79 0x158 0x3e4 0x0 0x0 0x0 0x79 0x15c 0x3e8 0x0 0x0 0x0 0x79>;
						linux,phandle = <0x3e>;
						phandle = <0x3e>;
					};

					lcdifctrlgrp {
						fsl,pins = <0x104 0x390 0x0 0x0 0x0 0x79 0x108 0x394 0x0 0x0 0x0 0x79 0x10c 0x398 0x5dc 0x0 0x0 0x79 0x110 0x39c 0x0 0x0 0x0 0x79>;
						linux,phandle = <0x3f>;
						phandle = <0x3f>;
					};

					pwm4grp {
						fsl,pins = <0x1a4 0x430 0x0 0x3 0x0 0x79>;
						linux,phandle = <0x13>;
						phandle = <0x13>;
					};

					pwm5grp {
						fsl,pins = <0x1b8 0x444 0x0 0x3 0x0 0x79>;
						linux,phandle = <0x29>;
						phandle = <0x29>;
					};

					pwm6grp {
						fsl,pins = <0xd8 0x364 0x0 0x2 0x0 0x79>;
						linux,phandle = <0x2a>;
						phandle = <0x2a>;
					};

					pwm7grp {
						fsl,pins = <0xdc 0x368 0x0 0x2 0x0 0x79>;
						linux,phandle = <0x2b>;
						phandle = <0x2b>;
					};

					uart1-grp {
						fsl,pins = <0x84 0x310 0x624 0x0 0x2 0x1b0b1 0x88 0x314 0x0 0x0 0x0 0x1b0b1 0x90 0x31c 0x0 0x0 0x0 0x1b0b1 0x8c 0x318 0x620 0x0 0x2 0x1b0b1>;
						linux,phandle = <0x10>;
						phandle = <0x10>;
					};

					uart1-ctrlgrp1 {
						fsl,pins = <0x50 0x2dc 0x0 0x5 0x0 0x1b0b1 0x160 0x3ec 0x0 0x5 0x0 0x1b0b1 0x4c 0x2d8 0x0 0x5 0x0 0x1b0b1 0x164 0x3f0 0x0 0x5 0x0 0x1b0b1>;
						linux,phandle = <0x11>;
						phandle = <0x11>;
					};

					uart2grp {
						fsl,pins = <0x94 0x320 0x62c 0x0 0x0 0x1b0b1 0x98 0x324 0x0 0x0 0x0 0x1b0b1 0x9c 0x328 0x628 0x0 0x0 0x1b0b1 0xa0 0x32c 0x0 0x0 0x0 0x1b0b1>;
						linux,phandle = <0x42>;
						phandle = <0x42>;
					};

					uart5grp {
						fsl,pins = <0x6c 0x2f8 0x644 0x8 0x2 0x1b0b1 0x70 0x2fc 0x0 0x8 0x0 0x1b0b1>;
						linux,phandle = <0x43>;
						phandle = <0x43>;
					};

					gpio_usbh_reg {
						fsl,pins = <0x64 0x2f0 0x0 0x5 0x0 0x1b0b1>;
						linux,phandle = <0x4d>;
						phandle = <0x4d>;
					};

					usdhc1grp {
						fsl,pins = <0x1c0 0x44c 0x0 0x0 0x0 0x17059 0x1bc 0x448 0x0 0x0 0x0 0x10059 0x1c4 0x450 0x0 0x0 0x0 0x17059 0x1c8 0x454 0x0 0x0 0x0 0x17059 0x1cc 0x458 0x0 0x0 0x0 0x17059 0x1d0 0x45c 0x0 0x0 0x0 0x17059>;
						linux,phandle = <0x31>;
						phandle = <0x31>;
					};

					usdhc1grp_100mhz {
						fsl,pins = <0x1c0 0x44c 0x0 0x0 0x0 0x170b9 0x1bc 0x448 0x0 0x0 0x0 0x100b9 0x1c4 0x450 0x0 0x0 0x0 0x170b9 0x1c8 0x454 0x0 0x0 0x0 0x170b9 0x1cc 0x458 0x0 0x0 0x0 0x170b9 0x1d0 0x45c 0x0 0x0 0x0 0x170b9>;
					};

					usdhc1grp_200mhz {
						fsl,pins = <0x1c0 0x44c 0x0 0x0 0x0 0x170f9 0x1bc 0x448 0x0 0x0 0x0 0x100f9 0x1c4 0x450 0x0 0x0 0x0 0x170b9 0x1c8 0x454 0x0 0x0 0x0 0x170b9 0x1cc 0x458 0x0 0x0 0x0 0x170b9 0x1d0 0x45c 0x0 0x0 0x0 0x170b9>;
					};

					usdhc2grp {
						fsl,pins = <0x1e4 0x470 0x67c 0x1 0x0 0x17059 0x1e8 0x474 0x680 0x1 0x0 0x17059 0x1ec 0x478 0x684 0x1 0x2 0x17059 0x1f0 0x47c 0x688 0x1 0x0 0x17059 0x1e0 0x46c 0x678 0x1 0x0 0x17059 0x1dc 0x468 0x670 0x1 0x0 0x17059 0x68 0x2f4 0x0 0x3 0x0 0x14>;
					};

					wdoggrp {
						fsl,pins = <0x114 0x3a0 0x0 0x4 0x0 0x30b0>;
						linux,phandle = <0x18>;
						phandle = <0x18>;
					};
				};

				imx6ull-eval-v3 {

					touchgpios {
						fsl,pins = <0x1b8 0x444 0x0 0x5 0x0 0x74 0xd8 0x364 0x0 0x5 0x0 0x14>;
						linux,phandle = <0x39>;
						phandle = <0x39>;
					};
				};
			};

			iomuxc-gpr@020e4000 {
				compatible = "fsl,imx6ul-iomuxc-gpr", "fsl,imx6q-iomuxc-gpr", "syscon";
				reg = <0x20e4000 0x4000>;
				linux,phandle = <0x12>;
				phandle = <0x12>;
			};

			mqs {
				compatible = "fsl,imx6sx-mqs";
				gpr = <0x12>;
				status = "disabled";
			};

			gpt@020e8000 {
				compatible = "fsl,imx6ul-gpt", "fsl,imx31-gpt";
				reg = <0x20e8000 0x4000>;
				interrupts = <0x0 0x6d 0x4>;
				clocks = <0x1 0x0 0x1 0x0>;
				clock-names = "ipg", "per";
			};

			sdma@020ec000 {
				compatible = "fsl,imx6ul-sdma", "fsl,imx35-sdma";
				reg = <0x20ec000 0x4000>;
				interrupts = <0x0 0x2 0x4>;
				clocks = <0x1 0xb8 0x1 0xb8>;
				clock-names = "ipg", "ahb";
				#dma-cells = <0x3>;
				iram = <0x6>;
				fsl,sdma-ram-script-name = "imx/sdma/sdma-imx6q.bin";
				status = "okay";
				linux,phandle = <0x9>;
				phandle = <0x9>;
			};

			pwm@020f0000 {
				compatible = "fsl,imx6ul-pwm", "fsl,imx27-pwm";
				reg = <0x20f0000 0x4000>;
				interrupts = <0x0 0x72 0x4>;
				clocks = <0x1 0xab 0x1 0xab>;
				clock-names = "ipg", "per";
				#pwm-cells = <0x3>;
				pinctrl-names = "default";
				pinctrl-0 = <0x29>;
				status = "okay";
			};

			pwm@020f4000 {
				compatible = "fsl,imx6ul-pwm", "fsl,imx27-pwm";
				reg = <0x20f4000 0x4000>;
				interrupts = <0x0 0x73 0x4>;
				clocks = <0x1 0xac 0x1 0xac>;
				clock-names = "ipg", "per";
				#pwm-cells = <0x3>;
				pinctrl-names = "default";
				pinctrl-0 = <0x2a>;
				status = "okay";
			};

			pwm@020f8000 {
				compatible = "fsl,imx6ul-pwm", "fsl,imx27-pwm";
				reg = <0x20f8000 0x4000>;
				interrupts = <0x0 0x74 0x4>;
				clocks = <0x1 0xad 0x1 0xad>;
				clock-names = "ipg", "per";
				#pwm-cells = <0x3>;
				pinctrl-names = "default";
				pinctrl-0 = <0x2b>;
				status = "okay";
			};

			pwm@020fc000 {
				compatible = "fsl,imx6ul-pwm", "fsl,imx27-pwm";
				reg = <0x20fc000 0x4000>;
				interrupts = <0x0 0x75 0x4>;
				clocks = <0x1 0xae 0x1 0xae>;
				clock-names = "ipg", "per";
				#pwm-cells = <0x3>;
				status = "disabled";
			};
		};

		aips-bus@02100000 {
			compatible = "fsl,aips-bus", "simple-bus";
			#address-cells = <0x1>;
			#size-cells = <0x1>;
			reg = <0x2100000 0x100000>;
			ranges;

			usb@02184000 {
				compatible = "fsl,imx6ul-usb", "fsl,imx27-usb";
				reg = <0x2184000 0x200>;
				interrupts = <0x0 0x2b 0x4>;
				clocks = <0x1 0xcd>;
				fsl,usbphy = <0x2c>;
				fsl,usbmisc = <0x2d 0x0>;
				fsl,anatop = <0x1e>;
				ahb-burst-config = <0x0>;
				tx-burst-size-dword = <0x10>;
				rx-burst-size-dword = <0x10>;
				status = "okay";
				dr_mode = "otg";
				srp-disable;
				hnp-disable;
				adp-disable;
				extcon = <0x2e 0x2e>;
				vbus-supply = <0x2f>;
			};

			usb@02184200 {
				compatible = "fsl,imx6ul-usb", "fsl,imx27-usb";
				reg = <0x2184200 0x200>;
				interrupts = <0x0 0x2a 0x4>;
				clocks = <0x1 0xcd>;
				fsl,usbphy = <0x30>;
				fsl,usbmisc = <0x2d 0x1>;
				ahb-burst-config = <0x0>;
				tx-burst-size-dword = <0x10>;
				rx-burst-size-dword = <0x10>;
				status = "okay";
				dr_mode = "host";
				vbus-supply = <0x2f>;
			};

			usbmisc@02184800 {
				#index-cells = <0x1>;
				compatible = "fsl,imx6ul-usbmisc", "fsl,imx6q-usbmisc";
				reg = <0x2184800 0x200>;
				linux,phandle = <0x2d>;
				phandle = <0x2d>;
			};

			ethernet@02188000 {
				compatible = "fsl,imx6ul-fec", "fsl,imx6q-fec";
				reg = <0x2188000 0x4000>;
				interrupts = <0x0 0x76 0x4 0x0 0x77 0x4>;
				clocks = <0x1 0x90 0x1 0x91 0x1 0x30 0x1 0x2c 0x1 0x2c>;
				clock-names = "ipg", "ahb", "ptp", "enet_clk_ref", "enet_out";
				stop-mode = <0x12 0x10 0x3>;
				fsl,num-tx-queues = <0x1>;
				fsl,num-rx-queues = <0x1>;
				fsl,magic-packet;
				fsl,wakeup_irq = <0x0>;
				status = "disabled";
			};

			usdhc@02190000 {
				compatible = "fsl,imx6ull-usdhc", "fsl,imx6sx-usdhc";
				reg = <0x2190000 0x4000>;
				interrupts = <0x0 0x16 0x4>;
				clocks = <0x1 0xce 0x1 0xce 0x1 0xce>;
				clock-names = "ipg", "ahb", "per";
				assigned-clocks = <0x1 0x40 0x1 0xce>;
				assigned-clock-parents = <0x1 0x26>;
				assigned-clock-rates = <0x0 0xbcd3d80>;
				bus-width = <0x4>;
				fsl,tuning-step = <0x2>;
				status = "okay";
				pinctrl-names = "default";
				pinctrl-0 = <0x31 0x32>;
				no-1-8-v;
				cd-gpios = <0x33 0x0 0x1>;
				disable-wp;
				enable-sdio-wakeup;
				keep-power-in-suspend;
				vmmc-supply = <0x34>;
			};

			usdhc@02194000 {
				compatible = "fsl,imx6ull-usdhc", "fsl,imx6sx-usdhc";
				reg = <0x2194000 0x4000>;
				interrupts = <0x0 0x17 0x4>;
				clocks = <0x1 0xcf 0x1 0xcf 0x1 0xcf>;
				clock-names = "ipg", "ahb", "per";
				assigned-clocks = <0x1 0x41 0x1 0xcf>;
				assigned-clock-parents = <0x1 0x26>;
				assigned-clock-rates = <0x0 0x7de2900>;
				bus-width = <0x4>;
				fsl,tuning-step = <0x2>;
				status = "disabled";
			};

			adc@02198000 {
				compatible = "fsl,imx6ul-adc", "fsl,vf610-adc";
				reg = <0x2198000 0x4000>;
				interrupts = <0x0 0x64 0x4>;
				clocks = <0x1 0x7b>;
				num-channels = <0xa>;
				clock-names = "adc";
				status = "okay";
				vref-supply = <0x35>;
			};

			i2c@021a0000 {
				#address-cells = <0x1>;
				#size-cells = <0x0>;
				compatible = "fsl,imx6ul-i2c", "fsl,imx21-i2c";
				reg = <0x21a0000 0x4000>;
				interrupts = <0x0 0x24 0x4>;
				clocks = <0x1 0x9c>;
				status = "okay";
				pinctrl-names = "default", "gpio";
				pinctrl-0 = <0x36>;
				pinctrl-1 = <0x37>;
				sda-gpios = <0x38 0x1d 0x1>;
				scl-gpios = <0x38 0x1c 0x1>;

				atmel_mxt_ts@4a {
					compatible = "atmel,maxtouch";
					pinctrl-names = "default";
					pinctrl-0 = <0x39>;
					reg = <0x4a>;
					interrupt-parent = <0x3a>;
					interrupts = <0x10 0x2>;
					reset-gpios = <0xf 0x5 0x0>;
					status = "disabled";
				};

				touchrevf0710a@10 {
					compatible = "touchrevolution,fusion-f0710a";
					pinctrl-names = "default";
					pinctrl-0 = <0x39>;
					reg = <0x10>;
					gpios = <0x3a 0x10 0x0 0xf 0x5 0x1>;
					status = "disabled";
				};

				m41t0m6@68 {
					compatible = "st,m41t0";
					reg = <0x68>;
				};
			};

			i2c@021a4000 {
				#address-cells = <0x1>;
				#size-cells = <0x0>;
				compatible = "fsl,imx6ul-i2c", "fsl,imx21-i2c";
				reg = <0x21a4000 0x4000>;
				interrupts = <0x0 0x25 0x4>;
				clocks = <0x1 0x9d>;
				status = "okay";
				clock-frequency = <0x9c40>;
				pinctrl-names = "default", "gpio";
				pinctrl-0 = <0x3b>;
				pinctrl-1 = <0x3c>;
				sda-gpios = <0x38 0x1f 0x1>;
				scl-gpios = <0x38 0x1e 0x1>;

				ad7879@2c {
					compatible = "adi,ad7879-1";
					pinctrl-names = "default";
					pinctrl-0 = <0x3d>;
					reg = <0x2c>;
					interrupt-parent = <0x33>;
					interrupts = <0x7 0x2>;
					touchscreen-max-pressure = <0x1000>;
					adi,resistance-plate-x = <0x78>;
					adi,first-conversion-delay = [03];
					adi,acquisition-time = [01];
					adi,median-filter-size = [02];
					adi,averaging = [01];
					adi,conversion-interval = [ff];
				};
			};

			i2c@021a8000 {
				#address-cells = <0x1>;
				#size-cells = <0x0>;
				compatible = "fsl,imx6ul-i2c", "fsl,imx21-i2c";
				reg = <0x21a8000 0x4000>;
				interrupts = <0x0 0x26 0x4>;
				clocks = <0x1 0x9e>;
				status = "disabled";
			};

			romcp@021ac000 {
				compatible = "fsl,imx6ul-romcp", "syscon";
				reg = <0x21ac000 0x4000>;
			};

			mmdc@021b0000 {
				compatible = "fsl,imx6ul-mmdc", "fsl,imx6q-mmdc";
				reg = <0x21b0000 0x4000>;
			};

			weim@021b8000 {
				compatible = "fsl,imx6ul-weim", "fsl,imx6q-weim";
				reg = <0x21b8000 0x4000>;
				interrupts = <0x0 0xe 0x4>;
				clocks = <0x1 0x0>;
			};

			ocotp-ctrl@021bc000 {
				compatible = "fsl,imx6ull-ocotp", "syscon";
				reg = <0x21bc000 0x4000>;
				clocks = <0x1 0xa5>;
				linux,phandle = <0x1f>;
				phandle = <0x1f>;
			};

			csu@021c0000 {
				compatible = "fsl,imx6ul-csu";
				reg = <0x21c0000 0x4000>;
				interrupts = <0x0 0x15 0x4>;
				status = "disabled";
			};

			csi@021c4000 {
				compatible = "fsl,imx6ul-csi", "fsl,imx6s-csi";
				reg = <0x21c4000 0x4000>;
				interrupts = <0x0 0x7 0x4>;
				clocks = <0x1 0x0 0x1 0x8a 0x1 0x0>;
				clock-names = "disp-axi", "csi_mclk", "disp_dcic";
				status = "disabled";
			};

			lcdif@021c8000 {
				compatible = "fsl,imx6ul-lcdif", "fsl,imx28-lcdif";
				reg = <0x21c8000 0x4000>;
				interrupts = <0x0 0x5 0x4>;
				clocks = <0x1 0xa2 0x1 0xa1 0x1 0x0>;
				clock-names = "pix", "axi", "disp_axi";
				status = "okay";
				pinctrl-names = "default";
				pinctrl-0 = <0x3e 0x3f>;
				display = <0x40>;

				lcd-display {
					bits-per-pixel = <0x10>;
					bus-width = <0x12>;
					linux,phandle = <0x40>;
					phandle = <0x40>;

					display-timings {
						native-mode = <0x41>;

						640x480 {
							clock-frequency = <0x18023d8>;
							hactive = <0x280>;
							vactive = <0x1e0>;
							hback-porch = <0x28>;
							hfront-porch = <0x18>;
							vback-porch = <0x20>;
							vfront-porch = <0xb>;
							hsync-len = <0x60>;
							vsync-len = <0x2>;
							de-active = <0x1>;
							hsync-active = <0x0>;
							vsync-active = <0x0>;
							pixelclk-active = <0x0>;
							linux,phandle = <0x41>;
							phandle = <0x41>;
						};

						800x480 {
							clock-frequency = <0x1fb81e0>;
							hactive = <0x320>;
							vactive = <0x1e0>;
							hback-porch = <0xd8>;
							hfront-porch = <0x28>;
							vback-porch = <0x23>;
							vfront-porch = <0xa>;
							hsync-len = <0x80>;
							vsync-len = <0x2>;
							de-active = <0x1>;
							hsync-active = <0x0>;
							vsync-active = <0x0>;
							pixelclk-active = <0x0>;
						};

						800x480pixclkact {
							clock-frequency = <0x1fb81e0>;
							hactive = <0x320>;
							vactive = <0x1e0>;
							hback-porch = <0xd8>;
							hfront-porch = <0x28>;
							vback-porch = <0x23>;
							vfront-porch = <0xa>;
							hsync-len = <0x80>;
							vsync-len = <0x2>;
							de-active = <0x1>;
							hsync-active = <0x0>;
							vsync-active = <0x0>;
							pixelclk-active = <0x1>;
						};

						800x600 {
							clock-frequency = <0x2625a00>;
							hactive = <0x320>;
							vactive = <0x258>;
							hback-porch = <0x58>;
							hfront-porch = <0x28>;
							vback-porch = <0x17>;
							vfront-porch = <0x1>;
							hsync-len = <0x80>;
							vsync-len = <0x4>;
							de-active = <0x1>;
							hsync-active = <0x1>;
							vsync-active = <0x1>;
							pixelclk-active = <0x0>;
						};

						1024x600 {
							clock-frequency = <0x2dc6c00>;
							hactive = <0x400>;
							vactive = <0x258>;
							hback-porch = <0x68>;
							hfront-porch = <0x2b>;
							vback-porch = <0x18>;
							vfront-porch = <0x14>;
							hsync-len = <0x5>;
							vsync-len = <0x5>;
							de-active = <0x1>;
							hsync-active = <0x0>;
							vsync-active = <0x0>;
							pixelclk-active = <0x0>;
						};

						1024x768 {
							clock-frequency = <0x3dfd240>;
							hactive = <0x400>;
							vactive = <0x300>;
							hback-porch = <0xa0>;
							hfront-porch = <0x18>;
							vback-porch = <0x1d>;
							vfront-porch = <0x3>;
							hsync-len = <0x88>;
							vsync-len = <0x6>;
							de-active = <0x1>;
							hsync-active = <0x0>;
							vsync-active = <0x0>;
							pixelclk-active = <0x0>;
						};
					};
				};
			};

			pxp@021cc000 {
				compatible = "fsl,imx6ull-pxp-dma", "fsl,imx7d-pxp-dma";
				reg = <0x21cc000 0x4000>;
				interrupts = <0x0 0x8 0x4 0x0 0x12 0x4>;
				clocks = <0x1 0x0 0x1 0xaf>;
				clock-names = "pxp_ipg", "pxp_axi";
				status = "okay";
			};

			qspi@021e0000 {
				#address-cells = <0x1>;
				#size-cells = <0x0>;
				compatible = "fsl,imx6ull-qspi", "fsl,imx6ul-qspi";
				reg = <0x21e0000 0x4000 0x60000000 0x10000000>;
				reg-names = "QuadSPI", "QuadSPI-memory";
				interrupts = <0x0 0x6b 0x4>;
				clocks = <0x1 0xb0 0x1 0xb0>;
				clock-names = "qspi_en", "qspi";
				status = "disabled";
			};

			serial@021e8000 {
				compatible = "fsl,imx6ul-uart", "fsl,imx6q-uart", "fsl,imx21-uart";
				reg = <0x21e8000 0x4000>;
				interrupts = <0x0 0x1b 0x4>;
				clocks = <0x1 0xbf 0x1 0xc0>;
				clock-names = "ipg", "per";
				dmas = <0x9 0x1b 0x4 0x0 0x9 0x1c 0x4 0x0>;
				dma-names = "rx", "tx";
				status = "okay";
				pinctrl-names = "default";
				pinctrl-0 = <0x42>;
				fsl,uart-has-rtscts;
				fsl,dte-mode;
			};

			serial@021ec000 {
				compatible = "fsl,imx6ul-uart", "fsl,imx6q-uart", "fsl,imx21-uart";
				reg = <0x21ec000 0x4000>;
				interrupts = <0x0 0x1c 0x4>;
				clocks = <0x1 0xc1 0x1 0xc2>;
				clock-names = "ipg", "per";
				dmas = <0x9 0x1d 0x4 0x0 0x9 0x1e 0x4 0x0>;
				dma-names = "rx", "tx";
				status = "disabled";
			};

			serial@021f0000 {
				compatible = "fsl,imx6ul-uart", "fsl,imx6q-uart", "fsl,imx21-uart";
				reg = <0x21f0000 0x4000>;
				interrupts = <0x0 0x1d 0x4>;
				clocks = <0x1 0xc3 0x1 0xc4>;
				clock-names = "ipg", "per";
				dmas = <0x9 0x1f 0x4 0x0 0x9 0x20 0x4 0x0>;
				dma-names = "rx", "tx";
				status = "disabled";
			};

			serial@021f4000 {
				compatible = "fsl,imx6ul-uart", "fsl,imx6q-uart", "fsl,imx21-uart";
				reg = <0x21f4000 0x4000>;
				interrupts = <0x0 0x1e 0x4>;
				clocks = <0x1 0xc5 0x1 0xc6>;
				clock-names = "ipg", "per";
				dmas = <0x9 0x21 0x4 0x0 0x9 0x22 0x4 0x0>;
				dma-names = "rx", "tx";
				status = "okay";
				pinctrl-names = "default";
				pinctrl-0 = <0x43>;
				fsl,dte-mode;
			};

			i2c@021f8000 {
				#address-cells = <0x1>;
				#size-cells = <0x0>;
				compatible = "fsl,imx6ul-i2c", "fsl,imx21-i2c";
				reg = <0x21f8000 0x4000>;
				interrupts = <0x0 0x23 0x4>;
				clocks = <0x1 0x9f>;
				status = "disabled";
			};

			serial@021fc000 {
				compatible = "fsl,imx6ul-uart", "fsl,imx6q-uart", "fsl,imx21-uart";
				reg = <0x21fc000 0x4000>;
				interrupts = <0x0 0x11 0x4>;
				clocks = <0x1 0xc7 0x1 0xc8>;
				clock-names = "ipg", "per";
				dmas = <0x9 0x0 0x4 0x0 0x9 0x2f 0x4 0x0>;
				dma-names = "rx", "tx";
				status = "disabled";
			};
		};

		aips-bus@02200000 {
			compatible = "fsl,aips-bus", "simple-bus";
			#address-cells = <0x1>;
			#size-cells = <0x1>;
			reg = <0x2200000 0x100000>;
			ranges;

			dcp@02280000 {
				compatible = "fsl,imx6sl-dcp";
				reg = <0x2280000 0x4000>;
				interrupts = <0x0 0x2e 0x4 0x0 0x2f 0x4 0x0 0x30 0x4>;
				clocks = <0x1 0xe7>;
				clock-names = "dcp";
			};

			rngb@02284000 {
				compatible = "fsl,imx6sl-rng", "fsl,imx-rng", "imx-rng";
				reg = <0x2284000 0x4000>;
				interrupts = <0x0 0x6 0x4>;
				clocks = <0x1 0x0>;
			};

			serial@02288000 {
				compatible = "fsl,imx6ul-uart", "fsl,imx6q-uart", "fsl,imx21-uart";
				reg = <0x2288000 0x4000>;
				interrupts = <0x0 0x28 0x4>;
				clocks = <0x1 0xcb 0x1 0xcc>;
				clock-names = "ipg", "per";
				dmas = <0x9 0x2d 0x4 0x0 0x9 0x2e 0x4 0x0>;
				dma-names = "rx", "tx";
				status = "disabled";
			};

			epdc@0228c000 {
				compatible = "fsl,imx7d-epdc";
				interrupts = <0x0 0x70 0x4>;
				reg = <0x228c000 0x4000>;
				clocks = <0x1 0xeb 0x1 0xec>;
				clock-names = "epdc_axi", "epdc_pix";
				status = "disabled";
			};

			iomuxc-snvs@02290000 {
				compatible = "fsl,imx6ull-iomuxc-snvs";
				reg = <0x2290000 0x10000>;
				pinctrl-names = "default";
				pinctrl-0 = <0x44 0x45 0x46>;

				imx6ull-colibri {

					snvs-hoggrp-1 {
						fsl,pins = <0x20 0x64 0x0 0x5 0x0 0x14 0x14 0x58 0x0 0x5 0x0 0x14 0x0 0x44 0x0 0x5 0x0 0x74 0x1c 0x60 0x0 0x5 0x0 0x14 0x28 0x6c 0x0 0x5 0x0 0x74>;
						linux,phandle = <0x44>;
						phandle = <0x44>;
					};

					snvs-hoggrp-2 {
						fsl,pins = <0x18 0x5c 0x0 0x5 0x0 0x74>;
						linux,phandle = <0x45>;
						phandle = <0x45>;
					};

					snvs-hoggrp-3 {
						fsl,pins = <0x4 0x48 0x0 0x5 0x0 0x14>;
						linux,phandle = <0x46>;
						phandle = <0x46>;
					};

					snvs-ad7879-int {
						fsl,pins = <0x24 0x68 0x0 0x5 0x0 0x100b0>;
						linux,phandle = <0x3d>;
						phandle = <0x3d>;
					};

					snvs-reg-sd-grp {
						fsl,pins = <0x2c 0x70 0x0 0x5 0x0 0x400100b0>;
						linux,phandle = <0x49>;
						phandle = <0x49>;
					};

					snvs-gpio_usbc_det {
						fsl,pins = <0x10 0x54 0x0 0x5 0x0 0x130b0>;
						linux,phandle = <0x4c>;
						phandle = <0x4c>;
					};

					snvs-gpiokeysgrp {
						fsl,pins = <0xc 0x50 0x0 0x5 0x0 0x130b0>;
						linux,phandle = <0x4b>;
						phandle = <0x4b>;
					};

					snvs-usdhc1-cd-grp {
						fsl,pins = <0x8 0x4c 0x0 0x5 0x0 0x1b0b0>;
						linux,phandle = <0x32>;
						phandle = <0x32>;
					};

					snvs-usdhc1-cd-grp-slp {
						fsl,pins = <0x8 0x4c 0x0 0x5 0x0 0x0>;
					};

					wifi-pdn {
						fsl,pins = <0x4 0x48 0x0 0x5 0x0 0x14>;
					};
				};
			};

			snvs-gpr@0x02294000 {
				compatible = "fsl, imx6ull-snvs-gpr";
				reg = <0x2294000 0x10000>;
			};
		};
	};

	reserved-memory {
		#address-cells = <0x1>;
		#size-cells = <0x1>;
		ranges;

		linux,cma {
			compatible = "shared-dma-pool";
			reusable;
			size = <0x8000000>;
			linux,cma-default;
		};
	};

	backlight {
		compatible = "pwm-backlight";
		pinctrl-names = "default";
		pinctrl-0 = <0x47>;
		enable-gpios = <0x38 0xb 0x0>;
		status = "okay";
		brightness-levels = <0x0 0x4 0x8 0x10 0x20 0x40 0x80 0xff>;
		default-brightness-level = <0x6>;
		pwms = <0x48 0x0 0x4c4b40 0x1>;
	};

	pxp_v4l2_out {
		compatible = "fsl,imx6ul-pxp-v4l2", "fsl,imx6sx-pxp-v4l2", "fsl,imx6sl-pxp-v4l2";
		status = "okay";
	};

	regulator-module-3v3 {
		compatible = "regulator-fixed";
		regulator-always-on;
		regulator-name = "+V3.3";
		regulator-min-microvolt = <0x325aa0>;
		regulator-max-microvolt = <0x325aa0>;
		linux,phandle = <0x4a>;
		phandle = <0x4a>;
	};

	regulator-module-3v3-avdd {
		compatible = "regulator-fixed";
		regulator-always-on;
		regulator-name = "+V3.3_AVDD_AUDIO";
		regulator-min-microvolt = <0x325aa0>;
		regulator-max-microvolt = <0x325aa0>;
		linux,phandle = <0x35>;
		phandle = <0x35>;
	};

	regulator@1 {
		compatible = "regulator-gpio";
		gpio = <0x33 0x9 0x0>;
		pinctrl-names = "default";
		pinctrl-0 = <0x49>;
		regulator-always-on;
		regulator-name = "V3.3_1.8_SD";
		regulator-min-microvolt = <0x1b7740>;
		regulator-max-microvolt = <0x325aa0>;
		states = <0x1b7740 0x1 0x325aa0 0x0>;
		vin-supply = <0x4a>;
	};

	regulator-soc-in {
		compatible = "regulator-fixed";
		regulator-min-microvolt = <0x137478>;
		regulator-max-microvolt = <0x137478>;
		regulator-name = "soc_in";
		regulator-type = "voltage";
		vin-supply = <0x4a>;
		linux,phandle = <0x4>;
		phandle = <0x4>;
	};

	regulator-eth-phy {
		compatible = "regulator-fixed";
		regulator-min-microvolt = <0x325aa0>;
		regulator-max-microvolt = <0x325aa0>;
		regulator-name = "eth_phy";
		regulator-type = "voltage";
		vin-supply = <0x4a>;
		clocks = <0x1 0x2e>;
		startup-delay-us = <0x249f0>;
		linux,phandle = <0x17>;
		phandle = <0x17>;
	};

	gpio-keys {
		compatible = "gpio-keys";
		pinctrl-names = "default";
		pinctrl-0 = <0x4b>;

		power {
			label = "Wake-Up";
			gpios = <0x33 0x1 0x0>;
			linux,code = <0x8f>;
			debounce-interval = <0xa>;
			gpio-key,wakeup;
		};
	};

	usbc_det {
		compatible = "linux,extcon-usb-gpio";
		debounce = <0x19>;
		id-gpio = <0x33 0x2 0x0>;
		pinctrl-names = "default";
		pinctrl-0 = <0x4c>;
		linux,phandle = <0x2e>;
		phandle = <0x2e>;
	};

	regulator-3v3 {
		compatible = "regulator-fixed";
		regulator-name = "3.3V";
		regulator-min-microvolt = <0x325aa0>;
		regulator-max-microvolt = <0x325aa0>;
		regulator-always-on;
		linux,phandle = <0x34>;
		phandle = <0x34>;
	};

	regulator-5v0 {
		compatible = "regulator-fixed";
		regulator-name = "5V";
		regulator-min-microvolt = <0x4c4b40>;
		regulator-max-microvolt = <0x4c4b40>;
		linux,phandle = <0x4e>;
		phandle = <0x4e>;
	};

	regulator-usbh-vbus {
		compatible = "regulator-fixed";
		pinctrl-names = "default";
		pinctrl-0 = <0x4d>;
		regulator-name = "VCC_USB[1-4]";
		regulator-min-microvolt = <0x4c4b40>;
		regulator-max-microvolt = <0x4c4b40>;
		gpio = <0x38 0x2 0x1>;
		vin-supply = <0x4e>;
		linux,phandle = <0x2f>;
		phandle = <0x2f>;
	};
};
